# STM32U375 register map
File version: 1.0
CPU: CM33 r0p1, little endian, MPU, FPU, 4 interrupt priority bits
Registers are 32-bit, read-write, reset 0x0 unless marked. A register's access mark holds for its fields unless they carry their own. Offsets are from the block's base; [hi:lo] are bit positions; {n}, {i} and the like mark numbered series; 'fields as' and 'values as' point back to an identical list.

## OPAMP — OPAMP Address block
Base 0x40007000
Same registers: SEC_OPAMP 0x50007000
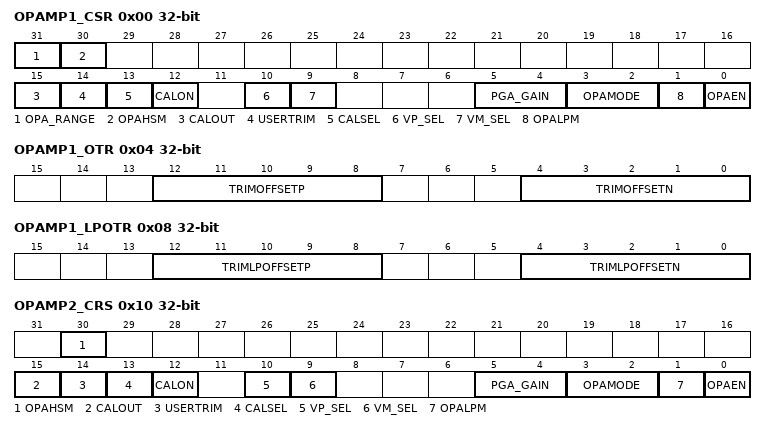
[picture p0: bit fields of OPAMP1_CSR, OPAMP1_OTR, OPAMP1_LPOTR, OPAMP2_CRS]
0x00 OPAMP1_CSR — OPAMP1 control/status register
  [31] OPA_RANGE — OPAMP range setting
    1=OPAMP range set
  [30] OPAHSM — OPAMP high-speed mode
    0=Normal mode (standard slew rate); 1=Increased consumption to improve the slew rate
  [15] CALOUT ro — OPAMP calibration output
  [14] USERTRIM — Selection of factory or user offset trimmed values
    0=Factory trim code used; 1=User trim code used
  [13] CALSEL — Calibration selection
    0=NMOS calibration (200mV applied on OPAMP inputs); 1=PMOS calibration (Vless thansub>DDA less than/sub>- 200 mV applied on OPAMP inputs)
  [12] CALON — Calibration mode enable
    0=Normal mode; 1=Calibration mode (all switches opened by hardware)
  [10] VP_SEL — Noninverted input selection
    0=GPIO connected to VINP; 1=DAC connected to VINP
  [9] VM_SEL — Inverting input selection
    0=GPIO connected to VINM (valid also in PGA mode for filtering); 1=Inverting input not externally connected
  [5:4] PGA_GAIN — OPAMP programmable amplifier gain value
    0=Internal PGA gain 2; 1=Internal PGA gain 4; 2=Internal PGA gain 8; 3=Internal PGA gain 16
  [3:2] OPAMODE — OPAMP PGA mode
    0=Internal PGA disabled; 1=Internal PGA disabled; 2=Internal PGA enabled, gain programmed in PGA_GAIN; 3=Internal follower
  [1] OPALPM — OPAMP low-power mode
    0=Normal mode; 1=Low-power mode
  [0] OPAEN — OPAMP enable
    0=OPAMP disabled; 1=OPAMP enabled
0x04 OPAMP1_OTR (reset mask 0xFFFF0000) — OPAMP1 offset trimming register in normal mode
  [12:8] TRIMOFFSETP — Trim for PMOS differential pairs
  [4:0] TRIMOFFSETN — Trim for NMOS differential pairs
0x08 OPAMP1_LPOTR (reset mask 0xFFFF0000) — OPAMP1 offset trimming register in low-power mode
  [12:8] TRIMLPOFFSETP — Low-power mode trim for PMOS differential pairs
  [4:0] TRIMLPOFFSETN — Low-power mode trim for NMOS differential pairs
0x10 OPAMP2_CRS — OPAMP2 control/status register
  [30] OPAHSM — OPAMP high-speed mode
    values as OPAMP1_CSR.OPAHSM
  [15] CALOUT ro — OPAMP calibration output
  [14] USERTRIM — Selection of factory or user offset trimmed values
    0=Factory trim code used; 1=User trim code used
  [13] CALSEL — Calibration selection
    0=NMOS calibration (200 mV applied on OPAMP inputs); 1=PMOS calibration (Vless thansub>DDA less than/sub>- 200 mV applied on OPAMP inputs)
  [12] CALON — Calibration mode enable
    values as OPAMP1_CSR.CALON
  [10] VP_SEL — Noninverted input selection
    0=GPIO connected to VINP; 1=DAC connected to VINP
  [9] VM_SEL — Inverting input selection
    values as OPAMP1_CSR.VM_SEL
  [5:4] PGA_GAIN — OPAMP programmable amplifier gain value
    values as OPAMP1_CSR.PGA_GAIN
  [3:2] OPAMODE — OPAMP PGA mode
    0=internal PGA disabled; 1=internal PGA disabled; 2=Internal PGA enabled, gain programmed in PGA_GAIN; 3=Internal follower
  [1] OPALPM — OPAMP low-power mode
    0=Normal mode; 1=Low-power mode
  [0] OPAEN — OPAMP enable
    0=OPAMP disabled; 1=OPAMP enabled
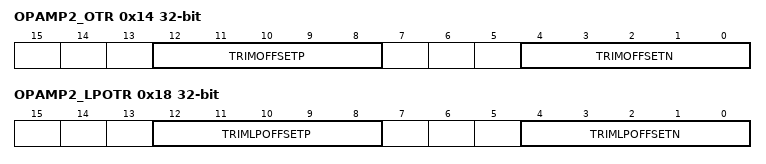
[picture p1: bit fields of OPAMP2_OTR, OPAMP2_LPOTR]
0x14 OPAMP2_OTR (reset mask 0xFFFF0000) — OPAMP2 offset trimming register in normal mode
  fields as OPAMP1_OTR
0x18 OPAMP2_LPOTR (reset mask 0xFFFF0000) — OPAMP2 offset trimming register in low-power mode
  fields as OPAMP1_LPOTR

## RAMCFG — RAMCFG address block description
Base 0x40026000
Same registers: SEC_RAMCFG 0x50026000
0x00 RAMCFG_M1CR — RAMCFG memory 1 control register
  [8] SRAMER — SRAM erase
    0=No erase operation ongoing; 1=Erase operation ongoing
0x08 RAMCFG_M1ISR ro — RAMCFG memory 1 interrupt status register
  [8] SRAMBUSY — SRAM busy with erase operation
    0=No erase operation ongoing; 1=Erase operation ongoing
0x28 RAMCFG_M1ERKEYR wo — RAMCFG memory 1 erase key register
  [7:0] ERASEKEY — Erase write protection key
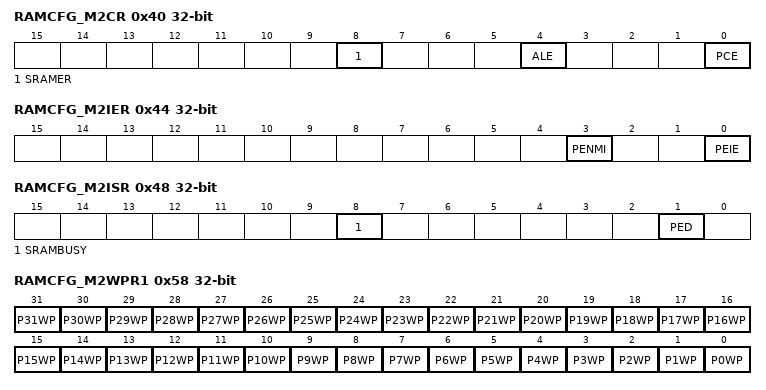
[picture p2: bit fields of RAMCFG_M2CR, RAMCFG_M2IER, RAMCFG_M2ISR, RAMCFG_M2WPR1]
0x40 RAMCFG_M2CR (reset mask 0xFFFFFFF0) — RAMCFG memory 2 control register
  [8] SRAMER — SRAM erase
    0=No erase operation ongoing; 1=Erase operation ongoing
  [4] ALE — Address latch enable in case of parity error
    0=Failing address not stored in the SRAM2 parity error address registers; 1=Failing address stored in the SRAM2 parity error address registers
  [0] PCE — Parity check enable
    0=Parity check disabled; 1=Parity check enabled
0x44 RAMCFG_M2IER — RAMCFG memory 2 interrupt enable register
  [3] PENMI — Parity error NMI
    0=NMI not generated in case of Parity error; 1=NMI generated in case of Parity error
  [0] PEIE — Parity error interrupt enable
    0=Parity error interrupt disabled; 1=Parity error interrupt enabled
0x48 RAMCFG_M2ISR ro — RAMCFG memory 2 interrupt status register
  [8] SRAMBUSY — SRAM busy with erase operation
    0=No erase operation ongoing; 1=Erase operation ongoing
  [1] PED — Parity error detected
    0=No Parity error detected; 1=Parity error detected
0x50 RAMCFG_M2PEAR ro — RAMCFG memory 2 parity error address register
  [31:0] PEA — Parity error address
0x54 RAMCFG_M2ICR — RAMCFG memory 2 interrupt clear register
  [1] CPED — Clear parity error detected
0x58 RAMCFG_M2WPR1 — RAMCFG memory 2 write protection register 1
  [all] fields
    0=Write protection of SRAM2 1-Kbyte page y is disabled; 1=Write protection of SRAM2 1-Kbyte page y is enabled
  [n] P{n}WP (n=0..31) — SRAM2 1-Kbyte page y write protection
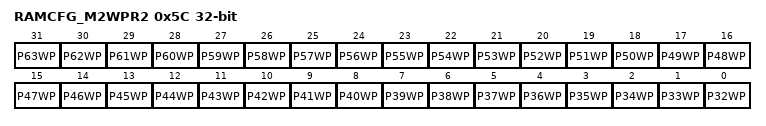
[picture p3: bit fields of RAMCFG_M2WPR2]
0x5C RAMCFG_M2WPR2 — RAMCFG memory 2 write protection register 2
  [all] fields
    values as the fields of RAMCFG_M2WPR1
  [n-32] P{n}WP (n=32..63) — SRAM2 1-Kbyte page y write protection
0x64 RAMCFG_M2PARKEYR wo — RAMCFG memory 2 parity key register
  [7:0] PARKEY — Parity write protection key
0x68 RAMCFG_M2ERKEYR wo — RAMCFG memory 2 erase key register
  [7:0] ERASEKEY — Erase write protection key
